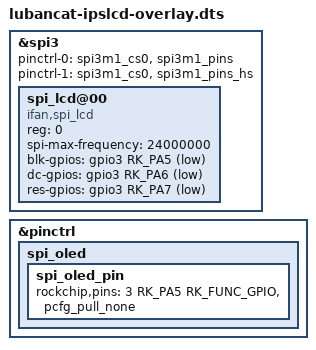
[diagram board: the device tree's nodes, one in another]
/*
 * Copyright (C) 2022 - All Rights Reserved by
 * EmbedFire LubanCat
 */
/dts-v1/;
/plugin/;

#include <dt-bindings/gpio/gpio.h>
#include <dt-bindings/pinctrl/rockchip.h>
#include <dt-bindings/clock/rk3568-cru.h>
#include <dt-bindings/interrupt-controller/irq.h>


/ {
	fragment@0 {
		target = <&spi3>;

		__overlay__ {
			status = "okay";
			#address-cells = <1>;
			#size-cells = <0>;
		
			// SPI gpio模拟多个cs信号 
			pinctrl-names = "default", "high_speed";
			pinctrl-0 = <&spi3m1_cs0 &spi3m1_pins>;
            pinctrl-1 = <&spi3m1_cs0 &spi3m1_pins_hs>;
			
			spi_lcd@00 {
				compatible = "ifan,spi_lcd";
				reg = <0>; //chip select 0:cs0  1:cs1
				spi-max-frequency = <24000000>; //spi output clock
				blk-gpios = <&gpio3 RK_PA5 GPIO_ACTIVE_LOW>;
				dc-gpios = <&gpio3 RK_PA6 GPIO_ACTIVE_LOW>;
				res-gpios = <&gpio3 RK_PA7 GPIO_ACTIVE_LOW>;
                //cs-gpios = <&gpio4 RK_PC6 GPIO_ACTIVE_LOW>;
                
			};
		};
	};
	fragment@1 {
		target = <&pinctrl>;

		__overlay__ {
			
			 spi_oled {
				spi_oled_pin: spi_oled_pin {
					rockchip,pins = <3 RK_PA7 RK_FUNC_GPIO &pcfg_pull_none>;
					rockchip,pins = <3 RK_PA6 RK_FUNC_GPIO &pcfg_pull_none>;
					rockchip,pins = <3 RK_PA5 RK_FUNC_GPIO &pcfg_pull_none>;
				};
			};

		};
	};
};
